# ESP32-S31 register map
Vendor: ESPRESSIF SYSTEMS (SHANGHAI) CO., LTD.; Series: ESP32 S-Series; File version: 1
CPU: RV32IMAFC r0p0, little endian, no MPU, FPU, 0 interrupt priority bits
Address unit: 32 bits
Registers are 32-bit, read-write, reset 0x0 unless marked. A register's access mark holds for its fields unless they carry their own. Offsets are from the block's base; [hi:lo] are bit positions; 'fields as' and 'values as' point back to an identical list; <NAME> marks a mode.

## USB_OTG_HS (part 2 of 5) — USB_OTG_HS Peripheral
Base 0x20300000
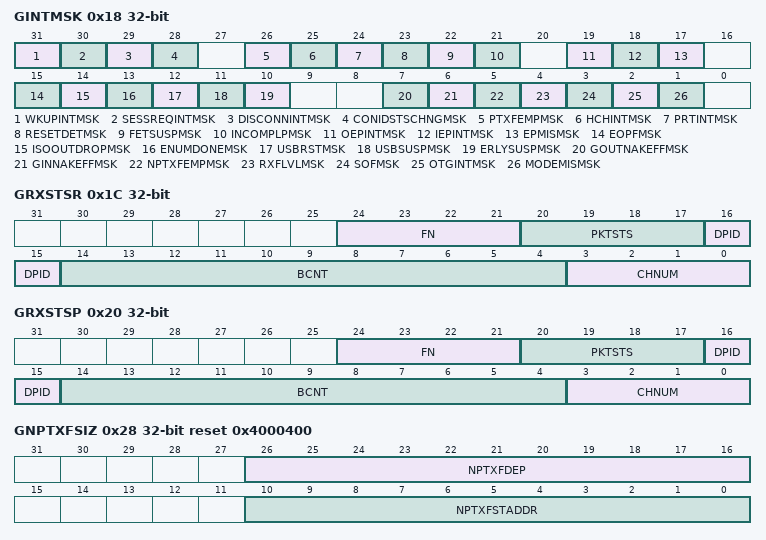
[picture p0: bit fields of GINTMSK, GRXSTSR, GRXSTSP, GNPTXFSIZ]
0x18 GINTMSK — This register works with the Interrupt Register (GINTSTS) to interrupt the application. When an interrupt bit is masked, the interrupt associated with that bit is not generated. However, the GINTSTS register bit corresponding to that interrupt is still set. Note: The fields of this register change depending on host or device mode.
  [31] WKUPINTMSK — Mode: Host and Device Resume/Remote Wakeup Detected Interrupt Mask (WkUpIntMsk) The WakeUp bit is used for LPM state wake up in a way similar to that of wake up in suspend state.
  [30] SESSREQINTMSK — Mode: Host and Device Session Request/New Session Detected Interrupt Mask (SessReqIntMsk)
  [29] DISCONNINTMSK — Mode: Host and Device Disconnect Detected Interrupt Mask (DisconnIntMsk)
  [28] CONIDSTSCHNGMSK — Mode: Host and Device Connector ID Status Change Mask (ConIDStsChngMsk)
  [26] PTXFEMPMSK — Mode: Host only Periodic TxFIFO Empty Mask (PTxFEmpMsk)
  [25] HCHINTMSK — Mode: Host only Host Channels Interrupt Mask (HChIntMsk)
  [24] PRTINTMSK — Mode: Host only Host Port Interrupt Mask (PrtIntMsk)
  [23] RESETDETMSK — Mode: Device only Reset detected Interrupt Mask (ResetDetMsk)
  [22] FETSUSPMSK — Mode: Device only Data Fetch Suspended Mask (FetSuspMsk)
  [21] INCOMPLPMSK — Incomplete Periodic Transfer Mask (incomplPMsk) Mode: Host only Incomplete Isochronous OUT Transfer Interrupt Mask (incompISOOUTMsk) Mode: Device only
  [19] OEPINTMSK — Mode: Device only OUT Endpoints Interrupt Mask (OEPIntMsk)
  [18] IEPINTMSK — Mode: Device only IN Endpoints Interrupt Mask (IEPIntMsk)
  [17] EPMISMSK — Mode: Device only Endpoint Mismatch Interrupt Mask (EPMisMsk)
  [15] EOPFMSK — Mode: Device only End of Periodic Frame Interrupt Mask (EOPFMsk)
  [14] ISOOUTDROPMSK — Mode: Device only Isochronous OUT Packet Dropped Interrupt Mask (ISOOutDropMsk)
  [13] ENUMDONEMSK — Mode: Device only Enumeration Done Mask (EnumDoneMsk)
  [12] USBRSTMSK — Mode: Device only USB Reset Mask (USBRstMsk)
  [11] USBSUSPMSK — Mode: Device only USB Suspend Mask (USBSuspMsk)
  [10] ERLYSUSPMSK — Mode: Device only Early Suspend Mask (ErlySuspMsk)
  [7] GOUTNAKEFFMSK — Mode: Device only Global OUT NAK Effective Mask (GOUTNakEffMsk)
  [6] GINNAKEFFMSK — Mode: Device only, Global Non-periodic IN NAK Effective Mask (GINNakEffMsk)
  [5] NPTXFEMPMSK — Mode: Host and Device Non-periodic TxFIFO Empty Mask (NPTxFEmpMsk)
  [4] RXFLVLMSK — Mode: Host and Device Receive FIFO Non-Empty Mask (RxFLvlMsk)
  [3] SOFMSK — Mode: Host and Device Start of (micro)Frame Mask (SofMsk)
  [2] OTGINTMSK — Mode: Host and Device OTG Interrupt Mask (OTGIntMsk)
  [1] MODEMISMSK — Mode: Host and Device Mode Mismatch Interrupt Mask (ModeMisMsk)
0x1C GRXSTSR ro — A read to the Receive Status Debug Read register returns the contents of the top of the Receive FIFO. The receive status contents must be interpreted differently in Host and Device modes. The core ignores the receive status read when the receive FIFO is empty and returns a value of 32'h0000_0000. Note: - Use of these fields vary based on whether the core is functioning as a host or a device. - Do not read this register's reset value before configuring the core because the read value is 'X' in the simulation.
  [24:21] FN — Mode: Device only Frame Number (FN) This is the least significant 4 bits of the (micro)Frame number in which the packet is received on the USB. This field is supported only when isochronous OUT endpoints are supported.
  [20:17] PKTSTS — Packet Status (PktSts) indicates the status of the received packet. In host mode, - 4'b0010: IN data packet received - 4'b0011: IN transfer completed (triggers an interrupt) - 4'b0101: Data toggle error (triggers an interrupt) - 4'b0111: Channel halted (triggers an interrupt) - Others: Reserved Reset:4'b0 In device mode, - 4'b0001: Global OUT NAK (triggers an interrupt) - 4'b0010: OUT data packet received - 4'b0011: OUT transfer completed (triggers an interrupt) - 4'b0100: SETUP transaction completed (triggers an interrupt) - 4'b0110: SETUP data packet received - Others: Reserved Reset:4'h0
  [16:15] DPID — Data PID (DPID) In host mode, indicates the Data PID of the received packet. In device mode, indicates the Data PID of the received OUT data packet. - 2'b00: DATA0 - 2'b10: DATA1 - 2'b01: DATA2 - 2'b11: MDATA Reset: 2'h0
  [14:4] BCNT — Byte Count (BCnt) In host mode, indicates the byte count of the received IN data packet. In device mode, indicates the byte count of the received data packet.
  [3:0] CHNUM — Channel Number (ChNum) Mode: Host only Indicates the channel number to which the current received packet belongs. Endpoint Number (EPNum) Mode: Device only Indicates the endpoint number to which the current received packet belongs.
0x20 GRXSTSP ro — A read to the Receive Status Read and Pop register returns the contents of the top of the Receive FIFO and additionally pops the top data entry out of the RxFIFO. The receive status contents must be interpreted differently in Host and Device modes. The core ignores the receive status pop/read when the receive FIFO is empty and returns a value of 32'h0000_0000. The application must only pop the Receive Status FIFO when the Receive FIFO Non-Empty bit of the Core Interrupt register (GINTSTS.RxFLvl) is asserted. Note: - Use of these fields vary based on whether the core is functioning as a host or a device. - Do not read this register's reset value before configuring the core because the read value is 'X' in the simulation.
  fields as GRXSTSR
0x24 GRXFSIZ reset 0x400 — The application can program the RAM size that must be allocated to the RxFIFO.
  [10:0] RXFDEP — Mode: Host and Device RxFIFO Depth (RxFDep) This value is in terms of 32-bit words. - Minimum value is 16 - Maximum value is 32,768 The power-on reset value of this register is specified as the Largest Rx Data FIFO Depth during configuration. If Enable Dynamic FIFO Sizing is selected in coreConsultant, these flops are optimized, and reads return the power-on value. If Enable Dynamic FIFO Sizing is selected in coreConsultant, you can write a new value in this field. Programmed values must not exceed the power-on value.
0x28 GNPTXFSIZ reset 0x4000400 — The application can program the RAM size and the memory start address for the Non-periodic TxFIFO Note: The fields of this register change depending on host or device mode.
  [26:16] NPTXFDEP — Mode: Host only Non-periodic TxFIFO Depth (NPTxFDep) For host mode, this field is always valid. For device mode, this field is valid only when OTG_EN_DED_TX_FIFO=0. This value is in terms of 32-bit words. - Minimum value is 16 - Maximum value is 32,768 This attribute of field is determined during coreConsultant configuration by Enable Dynamic FIFO Sizing? (OTG_DFIFO_DYNAMIC): - OTG_DFIFO_DYNAMIC = 0: These flops are optimized, and reads return the power-on value. - OTG_DFIFO_DYNAMIC = 1: The application can write a new value in this field. Programmed values must not exceed the power-on value set in coreConsultant. The power-on reset value of this field is specified during coreConsultant configuration as Largest IN Endpoint FIFO 0 Depth (parameter OTG_TX_DINEP_DFIFO_DEPTH_0).
  [10:0] NPTXFSTADDR — Non-periodic Transmit RAM Start Address (NPTxFStAddr) For host mode, this field is always valid. This field contains the memory start address for Non-periodic Transmit FIFO RAM. - This field is determined during coreConsultant configuration by Enable Dynamic FIFO Sizing? (OTG_DFIFO_DYNAMIC):OTG_DFIFO_DYNAMIC = 0 These flops are optimized, and reads return the power-on value. - OTG_DFIFO_DYNAMIC = 1 The application can write a new value in this field. Programmed values must not exceed the power-on value set in coreConsultant. Programmed values must not exceed the power-on value set in coreConsultant. The power-on reset value of this field is specified during coreConsultant configuration by Largest Rx Data FIFO Depth (parameter OTG_RX_DFIFO_DEPTH).
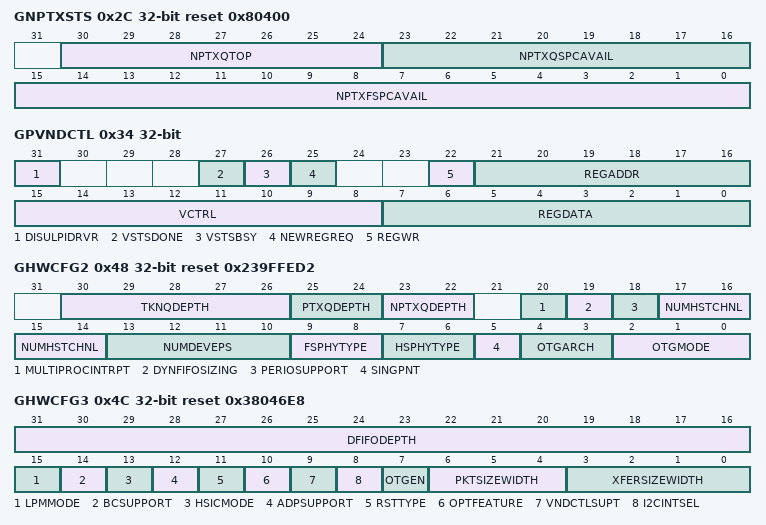
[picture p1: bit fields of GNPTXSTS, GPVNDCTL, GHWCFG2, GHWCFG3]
0x2C GNPTXSTS ro reset 0x80400 — In Device mode, this register is valid only in Shared FIFO operation. This read-only register contains the free space information for the Non-periodic TxFIFO and the Non-periodic Transmit Request Queue.
  [30:24] NPTXQTOP — Top of the Non-periodic Transmit Request Queue (NPTxQTop) Entry in the Non-periodic Tx Request Queue that is currently being processed by the MAC. - Bits [30:27]: Channel/endpoint number - Bits [26:25]: - 2'b00: IN/OUT token -- 2'b01: Zero-length transmit packet (device IN/host OUT) -- 2'b10: PING/CSPLIT token -- 2'b11: Channel halt command - Bit [24]: Terminate (last Entry for selected channel/endpoint) Reset: 7'h0
  [23:16] NPTXQSPCAVAIL — Non-periodic Transmit Request Queue Space Available (NPTxQSpcAvail) Indicates the amount of free space available in the Non-periodic Transmit Request Queue. This queue holds both IN and OUT requests in Host mode. Device mode has only IN requests. - 8'h0: Non-periodic Transmit Request Queue is full - 8'h1: 1 location available - 8'h2: 2 locations available - n: n locations available (0 <= n <= 8) - Others: Reserved Reset: Configurable
  [15:0] NPTXFSPCAVAIL — Non-periodic TxFIFO Space Avail (NPTxFSpcAvail) Indicates the amount of free space available in the Non-periodic TxFIFO. Values are in terms of 32-bit words. - 16'h0: Non-periodic TxFIFO is full - 16'h1: 1 word available - 16'h2: 2 words available - 16'hn: n words available (where 0 <= n <= 32,768) - 16'h8000: 32,768 words available - Others: Reserved Reset: Configurable
0x34 GPVNDCTL access per field — The application can use this register to access PHY registers. It is implemented only if Enable PHY Vendor Control Interface was selected during coreConsultant configuration (parameter OTG_VENDOR_CTL_INTERFACE = 1). For a UTMI+ PHY, the DWC_otg core uses the UTMI+ Vendor Control interface for PHY register access. For a ULPI PHY, the core uses the ULPI interface for PHY register access. The application sets Vendor Control register for PHY register access and times the PHY register access. The application polls the VStatus Done bit in this register for the completion of the PHY register access.
  [31] DISULPIDRVR rw — Disable ULPI Drivers (DisUlpiDrvr) The application sets this bit when it has finished processing the ULPI Carkit Interrupt (GINTSTS.ULPICKINT). When set, the controller disables drivers for output signals and masks input signal for the ULPI interface. The controller clears this bit before enabling the ULPI interface.
  [27] VSTSDONE rw — VStatus Done (VStsDone) The core sets this bit when the vendor control access is done. This bit is cleared by the core when the application sets the New Register Request bit (bit 25).
  [26] VSTSBSY ro — VStatus Busy (VStsBsy) The core sets this bit when the vendor control access is in progress and clears this bit when done.
  [25] NEWREGREQ rw — New Register Request (NewRegReq) The application sets this bit for a new vendor control access.
  [22] REGWR rw — Register Write (RegWr) Set this bit for register writes, and clear it for register reads.
  [21:16] REGADDR rw — Register Address (RegAddr) The 6-bit PHY register address for immediate PHY Register set access. Set to 6'h2F for Extended PHY Register set access.
  [15:8] VCTRL rw — UTMI+ Vendor Control Register Address (VCtrl) The 4-bit register address a vendor defined 4-bit parallel output bus. Bits 11:8 of this field are placed on utmi_vcontrol[3:0]. ULPI Extended Register Address (ExtRegAddr) The 6-bit PHY extended register address.
  [7:0] REGDATA rw — Register Data (RegData) Contains the write data for register write. Read data for register read, valid when VStatus Done is set.
0x40 GSNPSID ro reset 0x4F54430A — This read-only register contains the release number of the core being used.
  [31:0] SYNOPSYSID — Release number of the controller being used currently. Bits [31:16]: - 0x4f54: ASCII Value for OT Bits [15:0]: Current Release Number. For example, 0x400a corresponds to v4.00a Release number.
0x44 GHWCFG1 ro — This register contains the logical endpoint direction(s) selected using coreConsultant.
  [31:0] EPDIR — This 32-bit field uses two bits per endpoint to determine the endpoint direction. Endpoint - Bits [31:30]: Endpoint 15 direction - Bits [29:28]: Endpoint 14 direction ... - Bits [3:2]: Endpoint 1 direction - Bits[1:0]: Endpoint 0 direction (always BIDIR) Direction - 2'b00: BIDIR (IN and OUT) endpoint - 2'b01: IN endpoint - 2'b10: OUT endpoint - 2'b11: Reserved Note: This field is configured using the OTG_EP_DIR_1(n) parameter.
0x48 GHWCFG2 ro reset 0x239FFED2 — This register contains configuration options selected using coreConsultant.
  [30:26] TKNQDEPTH — Device Mode IN Token Sequence Learning Queue Depth (TknQDepth) Range: 0-30 Note: This field is configured using the OTG_TOKEN_QUEUE_DEPTH parameter.
  [25:24] PTXQDEPTH — Host Mode Periodic Request Queue Depth (PTxQDepth) - 2'b00: 2 - 2'b01: 4 - 2'b10: 8 - 2'b11:16 Note: This field is configured using the OTG_PERIO_TX_QUEUE_DEPTH parameter.
  [23:22] NPTXQDEPTH — Non-periodic Request Queue Depth (NPTxQDepth) - 2'b00: 2 - 2'b01: 4 - 2'b10: 8 - Others: Reserved Note: This field is configured using the OTG_NPERIO_TX_QUEUE_DEPTH parameter.
  [20] MULTIPROCINTRPT — Multi Processor Interrupt Enabled (MultiProcIntrpt) - 1'b0: No - 1'b1: Yes Note: This field is configured using the OTG_MULTI_PROC_INTRPT parameter.
  [19] DYNFIFOSIZING — Dynamic FIFO Sizing Enabled (DynFifoSizing) - 1'b0: No - 1'b1: Yes Note: This field is configured using the OTG_DFIFO_DYNAMIC parameter.
  [18] PERIOSUPPORT — Periodic OUT Channels Supported in Host Mode (PerioSupport) - 1'b0: No - 1'b1: Yes Note: This field is configured using the OTG_EN_PERIO_HOST parameter.
  [17:14] NUMHSTCHNL — Number of Host Channels (NumHstChnl) Indicates the number of host channels supported by the core in Host mode. The range of this field is 0-15: 0 specifies 1 channel, 15 specifies 16 channels. Note: This field is configured using the OTG_NUM_HOST_CHAN parameter.
  [13:10] NUMDEVEPS — Number of Device Endpoints (NumDevEps) Indicates the number of device endpoints supported by the core in Device mode. The range of this field is 0-15. Note: This field is configured using the OTG_NUM_EPS parameter.
  [9:8] FSPHYTYPE — Full-Speed PHY Interface Type (FSPhyType) - 2'b00: Full-speed interface not supported - 2'b01: Dedicated full-speed interface - 2'b10: FS pins shared with UTMI+ pins - 2'b11: FS pins shared with ULPI pins Note: This field is configured using the OTG_FSPHY_INTERFACE parameter.
  [7:6] HSPHYTYPE — High-Speed PHY Interface Type (HSPhyType) - 2'b00: High-Speed interface not supported - 2'b01: UTMI+ - 2'b10: ULPI - 2'b11: UTMI+ and ULPI Note: This field is configured using the OTG_HSPHY_INTERFACE parameter.
  [5] SINGPNT — Point-to-Point (SingPnt) - 1'b0: Multi-point application (hub and split support) - 1'b1: Single-point application (no hub and split support) Note: This field is configured using the OTG_SINGLE_POINT parameter.
  [4:3] OTGARCH — Architecture (OtgArch) - 2'b00: Slave-Only - 2'b01: External DMA - 2'b10: Internal DMA - Others: Reserved Note: This field is configured using the OTG_ARCHITECTURE parameter.
  [2:0] OTGMODE — Mode of Operation (OtgMode) - 3'b000: HNP- and SRP-Capable OTG (Host & Device) - 3'b001: SRP-Capable OTG (Host & Device) - 3'b010: Non-HNP and Non-SRP Capable OTG (Host and Device) - 3'b011: SRP-Capable Device - 3'b100: Non-OTG Device - 3'b101: SRP-Capable Host - 3'b110: Non-OTG Host - Others: Reserved Note: This field is configured using the OTG_MODE parameter.
0x4C GHWCFG3 ro reset 0x38046E8 — This register contains configuration options selected using coreConsultant.
  [31:16] DFIFODEPTH — DFIFO Depth (DfifoDepth - EP_LOC_CNT) This value is in terms of 32-bit words. - Minimum value is 32 - Maximum value is 32,768 Note: This field is configured using the OTG_DFIFO_DEPTH parameter. For more information on EP_LOC_CNT, see the Endpoint Information Controller (EPINFO_CTL) section.
  [15] LPMMODE — LPM mode specified for Mode of Operation.
  [14] BCSUPPORT — This bit indicates the controller support for Battery Charger. - 0 - No Battery Charger Support - 1 - Battery Charger support present
  [13] HSICMODE — HSIC mode specified for Mode of Operation Value Range: 0 - 1 - 1: HSIC-capable with shared UTMI PHY interface - 0: Non-HSIC-capable
  [12] ADPSUPPORT — This bit indicates whether ADP logic is present within or external to the controller - 0: No ADP logic present with the controller - 1: ADP logic is present along with the controller.
  [11] RSTTYPE — Reset Style for Clocked always Blocks in RTL (RstType) - 1'b0: Asynchronous reset is used in the controller - 1'b1: Synchronous reset is used in the controller Note: This field is configured using the OTG_SYNC_RESET_TYPE parameter.
  [10] OPTFEATURE — Optional Features Removed (OptFeature) Indicates whether the User ID register, GPIO interface ports, and SOF toggle and counter ports were removed for gate count optimization by enabling Remove Optional Features. - 1'b0: No - 1'b1: Yes Note: This field is configured using the OTG_RM_OPT_FEATURES parameter.
  [9] VNDCTLSUPT — Vendor Control Interface Support (VndctlSupt) - 1'b0: Vendor Control Interface is not available on the core. - 1'b1: Vendor Control Interface is available. Note: This field is configured using the OTG_VENDOR_CTL_INTERFACE parameter.
  [8] I2CINTSEL — I2C Selection (I2CIntSel) - 1'b0: I2C Interface is not available on the controller. - 1'b1: I2C Interface is available on the controller. Note: This field is configured using the OTG_I2C_INTERFACE parameter.
  [7] OTGEN — OTG Function Enabled (OtgEn) The application uses this bit to indicate the OTG capabilities of the controller . - 1'b0: Not OTG capable - 1'b1: OTG Capable Note: This field is configured using the OTG_MODE parameter.
  [6:4] PKTSIZEWIDTH — Width of Packet Size Counters (PktSizeWidth) - 3'b000: 4 bits - 3'b001: 5 bits - 3'b010: 6 bits - 3'b011: 7 bits - 3'b100: 8 bits - 3'b101: 9 bits - 3'b110: 10 bits - Others: Reserved Note: This field is configured using the OTG_PACKET_COUNT_WIDTH parameter.
  [3:0] XFERSIZEWIDTH — Width of Transfer Size Counters (XferSizeWidth) - 4'b0000: 11 bits - 4'b0001: 12 bits ... - 4'b1000: 19 bits - Others: Reserved Note: This field is configured using the OTG_PACKET_COUNT_WIDTH parameter.
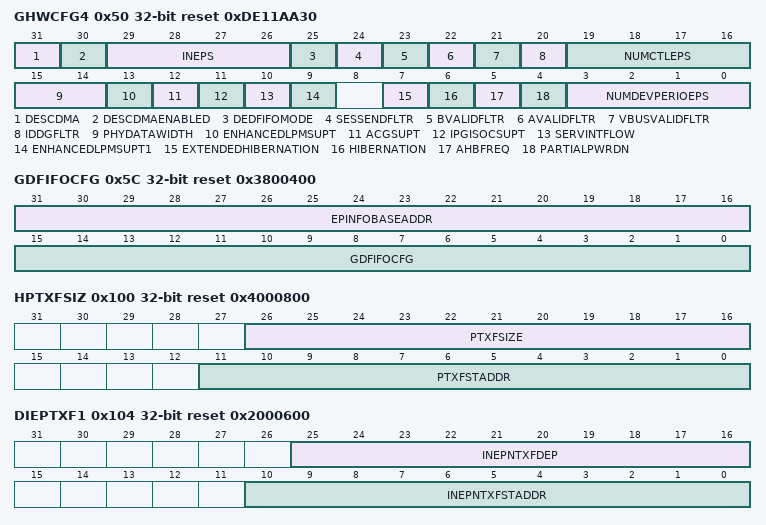
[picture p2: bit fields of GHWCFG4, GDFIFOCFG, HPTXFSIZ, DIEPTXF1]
0x50 GHWCFG4 ro reset 0xDE11AA30 — This register contains configuration options selected using coreConsultant. Note: Bit [31] is available only when Scatter/Gather DMA mode is enabled. When Scatter/Gather DMA mode is disabled, this field is reserved.
  [31] DESCDMA — Scatter/Gather DMA configuration - 1'b0: Non Dynamic configuration - 1'b1: Dynamic configuration Note: This field is configured using the OTG_EN_DESC_DMA parameter.
  [30] DESCDMAENABLED — Scatter/Gather DMA configuration - 1'b0: Non-Scatter/Gather DMA configuration - 1'b1: Scatter/Gather DMA configuration
  [29:26] INEPS — Number of Device Mode IN Endpoints Including Control Endpoints (INEps) - 0: 1 IN Endpoint - 1: 2 IN Endpoints .... - 15: 16 IN Endpoints
  [25] DEDFIFOMODE — Enable Dedicated Transmit FIFO for device IN Endpoints (DedFifoMode) - 1'b0 : Dedicated Transmit FIFO Operation not enabled. - 1'b1 : Dedicated Transmit FIFO Operation enabled.
  [24] SESSENDFLTR — session_end Filter Enabled (SessEndFltr) - 1'b0: No filter - 1'b1: Filter
  [23] BVALIDFLTR — b_valid Filter Enabled (BValidFltr) - 1'b0: No filter - 1'b1: Filter
  [22] AVALIDFLTR — a_valid Filter Enabled (AValidFltr) - 1'b0: No filter - 1'b1: Filter
  [21] VBUSVALIDFLTR — VBUS Valid Filter Enabled (VBusValidFltr) - 1'b0: No filter - 1'b1: Filter
  [20] IDDGFLTR — IDDIG Filter Enable (IddgFltr) - 1'b0: No filter - 1'b1: Filter
  [19:16] NUMCTLEPS — Number of Device Mode Control Endpoints in Addition to Endpoint 0 (NumCtlEps) Range: 0-15
  [15:14] PHYDATAWIDTH — UTMI+ PHY/ULPI-to-Internal UTMI+ Wrapper Data Width (PhyDataWidth)<vr>When a ULPI PHY is used, an internal wrapper converts ULPI to UTMI+. - 2'b00: 8 bits - 2'b01: 16 bits - 2'b10: 8/16 bits, software selectable - Others: Reserved
  [13] ENHANCEDLPMSUPT — Enhanced LPM Support (EnhancedLPMSupt) This bit indicates that the controller supports the following behavior: L1 Entry Behavior based on FIFO Status - TX FIFO - Accept L1 Request even if ISOC IN TX FIFO is not empty. - Reject L1 Request if Non-Periodic TX FIFO is not empty. - Ensure application can flush the TX FIFO while the Controller is in L1. - RX FIFO - Accept L1 Request even if RX FIFO (common to Periodic and Non-Periodic) is not empty. - Accept L1 Request but delay SLEEPM assertion until RX SINK Buffer is empty. Prevent L1 Entry if a Control Transfer is in progress on any Control Endpoint. Ability to Flush TxFIFO even if PHY Clock is gated.
  [12] ACGSUPT — Active Clock Gating Support This bit indicates that the controller supports the Dynamic (Switching) Power Reduction during periods when there is no USB and AHB Traffic. - 1'b0: Active Clock Gating is not enabled. - 1'b1: Active Clock Gating Enabled.
  [11] IPGISOCSUPT — Interpacket Gap ISOC OUT Worst-case Support (ipgisocSupt) This bit indicates that the controller supports the worst-case scenario of Rx followed by Rx Inter Packet Gap (IPG) (32-bit times) as per the UTMI Specification for any token following an ISOC OUT token. Without this support, when any token follows an ISOC OUT token with the worst-case IPG, the controller does not detect the followed token. The worst-case IPG of the controller without this support depends on the AHB and PHY clock frequency.By default IPG Support is enabled.
  [10] SERVINTFLOW — Service Interval Flow This bit indicates that the controller supports Service-Interval based scheduling flow for ISOC IN EPs.
  [9] ENHANCEDLPMSUPT1 — Enhanced LPM Support1 (EnhancedLPMSupt1) - This bit indicates that the controller supports L1 entry based on FIFO status. - Accept L1 Request even if Bulk/Interrupt TxFIFO is not empty.
  [7] EXTENDEDHIBERNATION — Enable Hibernation - 1'b0: Extended Hibernation feature not enabled - 1'b1: Extended Hibernation feature enabled
  [6] HIBERNATION — Enable Hibernation (Hibernation) - 1'b0: Hibernation feature not enabled - 1'b1: Hibernation feature enabled
  [5] AHBFREQ — Minimum AHB Frequency Less Than 60 MHz (AhbFreq) - 1'b0: No - 1'b1: Yes
  [4] PARTIALPWRDN — Enable Partial Power Down (PartialPwrDn) - 1'b0: Partial Power Down Not Enabled - 1'b1: Partial Power Down Enabled
  [3:0] NUMDEVPERIOEPS — Number of Device Mode Periodic IN Endpoints (NumDevPerioEps) Range: 0-15
0x5C GDFIFOCFG reset 0x3800400 — Register to configure the DFIFOs for the controller.
  [31:16] EPINFOBASEADDR — This field provides the start address of the EP info controller. The EP info controller manages the stored values in the last few locations of the SPRAM as listed below. - Host Buffer DMA mode: One location per channel is used in SPRAM to store the HCDMAn value. - Host Scatter/Gather DMA mode: Four locations per channel are used in SPRAM to store the Base Descriptor address, Current Descriptor address, Current Buffer Pointer, and the Status Quadlet. - Device Buffer DMA mode: One location per endpoint direction is used in SPRAM to store the DIEPDMA and DOEPDMA value. - Device Scatter/Gather DMA mode: Four locations per endpoint direction are used in SPRAM to store the Base Descriptor address, Current Descriptor address, Current Buffer Pointer and the Status Quadlet.
  [15:0] GDFIFOCFG — GDFIFOCfg This field is for dynamic programming of the DFIFO Size. This value takes effect only when the application programs a non zero value to this register. The value programmed must conform to the guidelines described in 'FIFO RAM Allocation'. The core does not have any corrective logic if the FIFO sizes are programmed incorrectly.
0x68 GINTMSK2 — This register works with the Interrupt Register (GINTSTS2) to interrupt the application. When an interrupt bit is masked, the interrupt associated with that bit is not generated. However, the GINTSTS2 register bit corresponding to that interrupt is still set. Note: The fields of this register change depending on host or device mode.
  [31:0] GINTMSK2 — Resvered
0x6C GINTSTS2 — This register interrupts the application for system-level events in the current mode (Device mode or Host mode). Some of the bits in this register are valid only in Host mode, while others are valid in Device mode only. This register also indicates the current mode. To clear the interrupt status bits of type R_SS_WC, the application must write 1'b1 to the bit. The application must clear the GINTSTS2 register at initialization before unmasking the interrupt bit to avoid any interrupts generated prior to initialization.
  [31:0] GINTSTS2 — Resvered
0x100 HPTXFSIZ reset 0x4000800 — This register holds the size and the memory start address of the Periodic TxFIFO. Note: Read the reset value of this register only after the following conditions: - If IDDIG_FILTER is disabled, read only after PHY clock is stable. - If IDDIG_FILTER is enabled, read only after the filter timer expires.
  [26:16] PTXFSIZE — Host Periodic TxFIFO Depth (PTxFSize) This value is in terms of 32-bit words. - Minimum value is 16 - Maximum value is 32,768 The power-on reset value of this register is specified as the Largest Host Mode Periodic Tx Data FIFO Depth. - If Enable Dynamic FIFO Sizing? was deselected in coreConsultant (parameter OTG_DFIFO_DYNAMIC = 0), these flops are optimized, and reads return the power-on value. - If Enable Dynamic FIFO Sizing? was selected in coreConsultant (parameter OTG_DFIFO_DYNAMIC = 1), you can write a new value in this field. Programmed values must not exceed the power-on value set in coreConsultant.
  [11:0] PTXFSTADDR — Host Periodic TxFIFO Start Address (PTxFStAddr) The power-on reset value of this register is the sum of the Largest Rx Data FIFO Depth and Largest Non-periodic Tx Data FIFO Depth.These parameters are: In shared FIFO operation: - OTG_RX_DFIFO_DEPTH + OTG_TX_NPERIO_DFIFO_DEPTH In dedicated FIFO mode: - OTG_RX_DFIFO_DEPTH + OTG_TX_HNPERIO_DFIFO_DEPTH If Enable Dynamic FIFO Sizing? was deselected in coreConsultant (parameter OTG_DFIFO_DYNAMIC = 0), these flops are optimized, and reads return the power-on value. If Enable Dynamic FIFO Sizing? was selected in coreConsultant (parameter OTG_DFIFO_DYNAMIC = 1), you can write a new value in this field. Programmed values must not exceed the power-on value set in coreConsultant.
0x104 DIEPTXF1 reset 0x2000600 — This register is valid only in dedicated FIFO mode (OTG_EN_DED_TX_FIFO=1). It holds the size and memory start address of IN endpoint TxFIFOs implemented in Device mode. Each FIFO holds the data for one IN endpoint. This register is repeated for instantiated IN endpoint FIFOs 1 to 15. For IN endpoint FIFO 0, use GNPTXFSIZ register for programming the size and memory start address.
  [25:16] INEPNTXFDEP — IN Endpoint TxFIFO Depth (INEPnTxFDep) This value is in terms of 32-bit words. - Minimum value is 16 - Maximum value is 32,768 The power-on reset value of this register is specified as the Largest IN Endpoint FIFO number Depth (parameter OTG_TX_DINEP_DFIFO_DEPTH_i) set during coreConsultant configuration, where i is the FIFO number this register corresponds to. - If Enable Dynamic FIFO Sizing? was deselected in coreConsultant (parameter OTG_DFIFO_DYNAMIC = 0), these flops are optimized, and reads return the power-on value. - If Enable Dynamic FIFO Sizing? was selected in coreConsultant (parameter OTG_DFIFO_DYNAMIC = 1), you can write a new value in this field. Programmed values must not exceed the power-on value.
  [10:0] INEPNTXFSTADDR — IN Endpoint FIFOn Transmit RAM Start Address (INEPnTxFStAddr) This field contains the memory start address for the IN endpoint Transmit FIFO that this register corresponds to. The power-on reset value of this register is calculated according to the following formula: OTG_RX_DFIFO_DEPTH + SUM of OTG_TX_DINEP_DFIFO_DEPTH_'n', where n = 0 to (FIFO number-1). For example, Start address of INEP FIFO 1 (DIEPTXF1) is OTG_RX_DFIFO_DEPTH + OTG_TX_DINEP_DFIFO_DEPTH_0, start address of INEP FIFO 2 (DIEPTXF2) is OTG_RX_DFIFO_DEPTH + OTG_TX_DINEP_DFIFO_DEPTH_0 + OTG_TX_DINEP_DFIFO_DEPTH_1, and so on. If at POR the calculated value (C) exceeds 65535, then the Reset value becomes Reset Value(A) = (C-65536). - If Enable Dynamic FIFO Sizing is deselected in coreConsultant (OTG_DFIFO_DYNAMIC = 0), this field is read-only and read value is the power-on reset value. - If Enable Dynamic FIFO Sizing is selected in coreConsultant (OTG_DFIFO_DYNAMIC = 1), and you have calculated or programmed a new value for RxFIFO depth or TX FIFO depths, you can program their values according to the above formula. Programmed values must not exceed the power-on value set in coreConsultant.
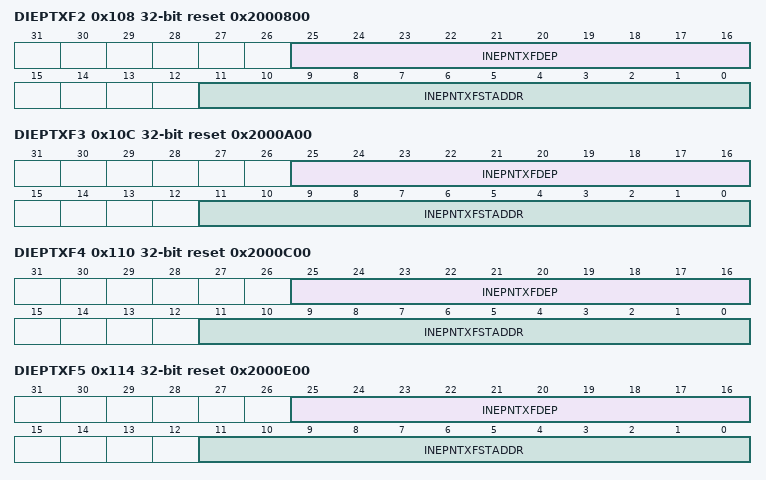
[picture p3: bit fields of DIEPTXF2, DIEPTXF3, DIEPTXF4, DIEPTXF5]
0x108 DIEPTXF2 reset 0x2000800 — This register is valid only in dedicated FIFO mode (OTG_EN_DED_TX_FIFO=1). It holds the size and memory start address of IN endpoint TxFIFOs implemented in Device mode. Each FIFO holds the data for one IN endpoint. This register is repeated for instantiated IN endpoint FIFOs 1 to 15. For IN endpoint FIFO 0, use GNPTXFSIZ register for programming the size and memory start address.
  [25:16] INEPNTXFDEP — IN Endpoint TxFIFO Depth (INEPnTxFDep) This value is in terms of 32-bit words. - Minimum value is 16 - Maximum value is 32,768 The power-on reset value of this register is specified as the Largest IN Endpoint FIFO number Depth (parameter OTG_TX_DINEP_DFIFO_DEPTH_i) set during coreConsultant configuration, where i is the FIFO number this register corresponds to. - If Enable Dynamic FIFO Sizing? was deselected in coreConsultant (parameter OTG_DFIFO_DYNAMIC = 0), these flops are optimized, and reads return the power-on value. - If Enable Dynamic FIFO Sizing? was selected in coreConsultant (parameter OTG_DFIFO_DYNAMIC = 1), you can write a new value in this field. Programmed values must not exceed the power-on value.
  [11:0] INEPNTXFSTADDR — IN Endpoint FIFOn Transmit RAM Start Address (INEPnTxFStAddr) This field contains the memory start address for the IN endpoint Transmit FIFO that this register corresponds to. The power-on reset value of this register is calculated according to the following formula: OTG_RX_DFIFO_DEPTH + SUM of OTG_TX_DINEP_DFIFO_DEPTH_'n', where n = 0 to (FIFO number-1). For example, Start address of INEP FIFO 1 (DIEPTXF1) is OTG_RX_DFIFO_DEPTH + OTG_TX_DINEP_DFIFO_DEPTH_0, start address of INEP FIFO 2 (DIEPTXF2) is OTG_RX_DFIFO_DEPTH + OTG_TX_DINEP_DFIFO_DEPTH_0 + OTG_TX_DINEP_DFIFO_DEPTH_1, and so on. If at POR the calculated value (C) exceeds 65535, then the Reset value becomes Reset Value(A) = (C-65536). - If Enable Dynamic FIFO Sizing is deselected in coreConsultant (OTG_DFIFO_DYNAMIC = 0), this field is read-only and read value is the power-on reset value. - If Enable Dynamic FIFO Sizing is selected in coreConsultant (OTG_DFIFO_DYNAMIC = 1), and you have calculated or programmed a new value for RxFIFO depth or TX FIFO depths, you can program their values according to the above formula. Programmed values must not exceed the power-on value set in coreConsultant.
0x10C DIEPTXF3 reset 0x2000A00 — This register is valid only in dedicated FIFO mode (OTG_EN_DED_TX_FIFO=1). It holds the size and memory start address of IN endpoint TxFIFOs implemented in Device mode. Each FIFO holds the data for one IN endpoint. This register is repeated for instantiated IN endpoint FIFOs 1 to 15. For IN endpoint FIFO 0, use GNPTXFSIZ register for programming the size and memory start address.
  fields as DIEPTXF2
0x110 DIEPTXF4 reset 0x2000C00 — This register is valid only in dedicated FIFO mode (OTG_EN_DED_TX_FIFO=1). It holds the size and memory start address of IN endpoint TxFIFOs implemented in Device mode. Each FIFO holds the data for one IN endpoint. This register is repeated for instantiated IN endpoint FIFOs 1 to 15. For IN endpoint FIFO 0, use GNPTXFSIZ register for programming the size and memory start address.
  fields as DIEPTXF2
0x114 DIEPTXF5 reset 0x2000E00 — This register is valid only in dedicated FIFO mode (OTG_EN_DED_TX_FIFO=1). It holds the size and memory start address of IN endpoint TxFIFOs implemented in Device mode. Each FIFO holds the data for one IN endpoint. This register is repeated for instantiated IN endpoint FIFOs 1 to 15. For IN endpoint FIFO 0, use GNPTXFSIZ register for programming the size and memory start address.
  fields as DIEPTXF2
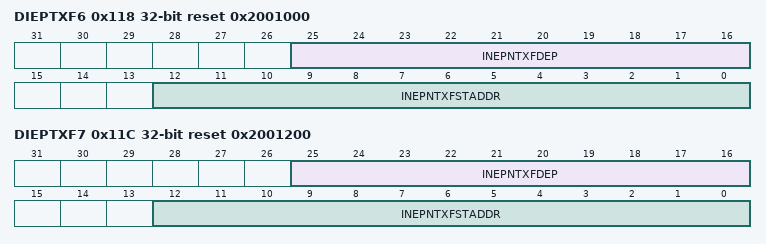
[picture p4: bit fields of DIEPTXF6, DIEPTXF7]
0x118 DIEPTXF6 reset 0x2001000 — This register is valid only in dedicated FIFO mode (OTG_EN_DED_TX_FIFO=1). It holds the size and memory start address of IN endpoint TxFIFOs implemented in Device mode. Each FIFO holds the data for one IN endpoint. This register is repeated for instantiated IN endpoint FIFOs 1 to 15. For IN endpoint FIFO 0, use GNPTXFSIZ register for programming the size and memory start address.
  [25:16] INEPNTXFDEP — IN Endpoint TxFIFO Depth (INEPnTxFDep) This value is in terms of 32-bit words. - Minimum value is 16 - Maximum value is 32,768 The power-on reset value of this register is specified as the Largest IN Endpoint FIFO number Depth (parameter OTG_TX_DINEP_DFIFO_DEPTH_i) set during coreConsultant configuration, where i is the FIFO number this register corresponds to. - If Enable Dynamic FIFO Sizing? was deselected in coreConsultant (parameter OTG_DFIFO_DYNAMIC = 0), these flops are optimized, and reads return the power-on value. - If Enable Dynamic FIFO Sizing? was selected in coreConsultant (parameter OTG_DFIFO_DYNAMIC = 1), you can write a new value in this field. Programmed values must not exceed the power-on value.
  [12:0] INEPNTXFSTADDR — IN Endpoint FIFOn Transmit RAM Start Address (INEPnTxFStAddr) This field contains the memory start address for the IN endpoint Transmit FIFO that this register corresponds to. The power-on reset value of this register is calculated according to the following formula: OTG_RX_DFIFO_DEPTH + SUM of OTG_TX_DINEP_DFIFO_DEPTH_'n', where n = 0 to (FIFO number-1). For example, Start address of INEP FIFO 1 (DIEPTXF1) is OTG_RX_DFIFO_DEPTH + OTG_TX_DINEP_DFIFO_DEPTH_0, start address of INEP FIFO 2 (DIEPTXF2) is OTG_RX_DFIFO_DEPTH + OTG_TX_DINEP_DFIFO_DEPTH_0 + OTG_TX_DINEP_DFIFO_DEPTH_1, and so on. If at POR the calculated value (C) exceeds 65535, then the Reset value becomes Reset Value(A) = (C-65536). - If Enable Dynamic FIFO Sizing is deselected in coreConsultant (OTG_DFIFO_DYNAMIC = 0), this field is read-only and read value is the power-on reset value. - If Enable Dynamic FIFO Sizing is selected in coreConsultant (OTG_DFIFO_DYNAMIC = 1), and you have calculated or programmed a new value for RxFIFO depth or TX FIFO depths, you can program their values according to the above formula. Programmed values must not exceed the power-on value set in coreConsultant.
0x11C DIEPTXF7 reset 0x2001200 — This register is valid only in dedicated FIFO mode (OTG_EN_DED_TX_FIFO=1). It holds the size and memory start address of IN endpoint TxFIFOs implemented in Device mode. Each FIFO holds the data for one IN endpoint. This register is repeated for instantiated IN endpoint FIFOs 1 to 15. For IN endpoint FIFO 0, use GNPTXFSIZ register for programming the size and memory start address.
  fields as DIEPTXF6
